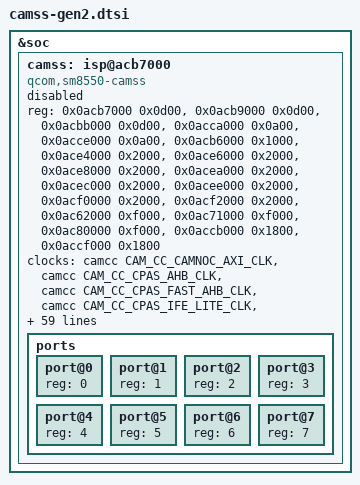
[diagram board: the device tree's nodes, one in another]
#include <dt-bindings/interrupt-controller/arm-gic.h>
#include <dt-bindings/clock/qcom,camcc-kalama.h>
#include <dt-bindings/clock/qcom,dispcc-kalama.h>
#include <dt-bindings/clock/qcom,gcc-kalama.h>
#include <dt-bindings/clock/qcom,gpucc-kalama.h>
#include <dt-bindings/clock/qcom,rpmh.h>
#include <dt-bindings/clock/qcom,tcsrcc-kalama.h>
#include <dt-bindings/clock/qcom,videocc-kalama.h>
#include <dt-bindings/regulator/qcom,rpmh-regulator-levels.h>
#include <dt-bindings/interconnect/qcom,kalama.h>
#include <dt-bindings/soc/qcom,ipcc.h>
#include <dt-bindings/soc/qcom,rpmh-rsc.h>
#include <dt-bindings/interconnect/qcom,icc.h>
#include <dt-bindings/spmi/spmi.h>
#include <dt-bindings/power/qcom-aoss-qmp.h>
#include <dt-bindings/clock/qcom,aop-qmp.h>

#include "camss-cci.dtsi"

&soc {
	#address-cells = <1>;
	#size-cells = <1>;

	camss: isp@acb7000 {
		compatible = "qcom,sm8550-camss";
		status = "disabled";

		reg = <0x0acb7000 0x0d00>,
		      <0x0acb9000 0x0d00>,
		      <0x0acbb000 0x0d00>,
		      <0x0acca000 0x0a00>,
		      <0x0acce000 0x0a00>,
		      <0x0acb6000 0x1000>,
		      <0x0ace4000 0x2000>,
		      <0x0ace6000 0x2000>,
		      <0x0ace8000 0x2000>,
		      <0x0acea000 0x2000>,
		      <0x0acec000 0x2000>,
		      <0x0acee000 0x2000>,
		      <0x0acf0000 0x2000>,
		      <0x0acf2000 0x2000>,
		      <0x0ac62000 0xf000>,
		      <0x0ac71000 0xf000>,
		      <0x0ac80000 0xf000>,
		      <0x0accb000 0x1800>,
		      <0x0accf000 0x1800>;
		reg-names = "csid0",
			    "csid1",
			    "csid2",
			    "csid_lite0",
			    "csid_lite1",
			    "csid_wrapper",
			    "csiphy0",
			    "csiphy1",
			    "csiphy2",
			    "csiphy3",
			    "csiphy4",
			    "csiphy5",
			    "csiphy6",
			    "csiphy7",
			    "vfe0",
			    "vfe1",
			    "vfe2",
			    "vfe_lite0",
			    "vfe_lite1";

		clocks = <&camcc CAM_CC_CAMNOC_AXI_CLK>,
			 <&camcc CAM_CC_CPAS_AHB_CLK>,
			 <&camcc CAM_CC_CPAS_FAST_AHB_CLK>,
			 <&camcc CAM_CC_CPAS_IFE_LITE_CLK>,
			 <&camcc CAM_CC_CPAS_IFE_0_CLK>,
			 <&camcc CAM_CC_CPAS_IFE_1_CLK>,
			 <&camcc CAM_CC_CPAS_IFE_2_CLK>,
			 <&camcc CAM_CC_CSID_CLK>,
			 <&camcc CAM_CC_CSIPHY0_CLK>,
			 <&camcc CAM_CC_CSI0PHYTIMER_CLK>,
			 <&camcc CAM_CC_CSIPHY1_CLK>,
			 <&camcc CAM_CC_CSI1PHYTIMER_CLK>,
			 <&camcc CAM_CC_CSIPHY2_CLK>,
			 <&camcc CAM_CC_CSI2PHYTIMER_CLK>,
			 <&camcc CAM_CC_CSIPHY3_CLK>,
			 <&camcc CAM_CC_CSI3PHYTIMER_CLK>,
			 <&camcc CAM_CC_CSIPHY4_CLK>,
			 <&camcc CAM_CC_CSI4PHYTIMER_CLK>,
			 <&camcc CAM_CC_CSIPHY5_CLK>,
			 <&camcc CAM_CC_CSI5PHYTIMER_CLK>,
			 <&camcc CAM_CC_CSIPHY6_CLK>,
			 <&camcc CAM_CC_CSI6PHYTIMER_CLK>,
			 <&camcc CAM_CC_CSIPHY7_CLK>,
			 <&camcc CAM_CC_CSI7PHYTIMER_CLK>,
			 <&camcc CAM_CC_CSID_CSIPHY_RX_CLK>,
			 <&gcc GCC_CAMERA_HF_AXI_CLK>,
			 <&camcc CAM_CC_IFE_0_CLK>,
			 <&camcc CAM_CC_IFE_0_FAST_AHB_CLK>,
			 <&camcc CAM_CC_IFE_1_CLK>,
			 <&camcc CAM_CC_IFE_1_FAST_AHB_CLK>,
			 <&camcc CAM_CC_IFE_2_CLK>,
			 <&camcc CAM_CC_IFE_2_FAST_AHB_CLK>,
			 <&camcc CAM_CC_IFE_LITE_CLK>,
			 <&camcc CAM_CC_IFE_LITE_AHB_CLK>,
			 <&camcc CAM_CC_IFE_LITE_CPHY_RX_CLK>,
			 <&camcc CAM_CC_IFE_LITE_CSID_CLK>;
		clock-names = "camnoc_axi",
			      "cpas_ahb",
			      "cpas_fast_ahb_clk",
			      "cpas_ife_lite",
			      "cpas_vfe0",
			      "cpas_vfe1",
			      "cpas_vfe2",
			      "csid",
			      "csiphy0",
			      "csiphy0_timer",
			      "csiphy1",
			      "csiphy1_timer",
			      "csiphy2",
			      "csiphy2_timer",
			      "csiphy3",
			      "csiphy3_timer",
			      "csiphy4",
			      "csiphy4_timer",
			      "csiphy5",
			      "csiphy5_timer",
			      "csiphy6",
			      "csiphy6_timer",
			      "csiphy7",
			      "csiphy7_timer",
			      "csiphy_rx",
			      "gcc_axi_hf",
			      "vfe0",
			      "vfe0_fast_ahb",
			      "vfe1",
			      "vfe1_fast_ahb",
			      "vfe2",
			      "vfe2_fast_ahb",
			      "vfe_lite",
			      "vfe_lite_ahb",
			      "vfe_lite_cphy_rx",
			      "vfe_lite_csid";

		interrupts = <GIC_SPI 601 IRQ_TYPE_EDGE_RISING>,
			     <GIC_SPI 603 IRQ_TYPE_EDGE_RISING>,
			     <GIC_SPI 431 IRQ_TYPE_EDGE_RISING>,
			     <GIC_SPI 605 IRQ_TYPE_EDGE_RISING>,
			     <GIC_SPI 376 IRQ_TYPE_EDGE_RISING>,
			     <GIC_SPI 477 IRQ_TYPE_EDGE_RISING>,
			     <GIC_SPI 478 IRQ_TYPE_EDGE_RISING>,
			     <GIC_SPI 479 IRQ_TYPE_EDGE_RISING>,
			     <GIC_SPI 448 IRQ_TYPE_EDGE_RISING>,
			     <GIC_SPI 122 IRQ_TYPE_EDGE_RISING>,
			     <GIC_SPI 89 IRQ_TYPE_EDGE_RISING>,
			     <GIC_SPI 278 IRQ_TYPE_EDGE_RISING>,
			     <GIC_SPI 277 IRQ_TYPE_EDGE_RISING>,
			     <GIC_SPI 602 IRQ_TYPE_EDGE_RISING>,
			     <GIC_SPI 604 IRQ_TYPE_EDGE_RISING>,
			     <GIC_SPI 688 IRQ_TYPE_EDGE_RISING>,
			     <GIC_SPI 606 IRQ_TYPE_EDGE_RISING>,
			     <GIC_SPI 377 IRQ_TYPE_EDGE_RISING>;
		interrupt-names = "csid0",
				  "csid1",
				  "csid2",
				  "csid_lite0",
				  "csid_lite1",
				  "csiphy0",
				  "csiphy1",
				  "csiphy2",
				  "csiphy3",
				  "csiphy4",
				  "csiphy5",
				  "csiphy6",
				  "csiphy7",
				  "vfe0",
				  "vfe1",
				  "vfe2",
				  "vfe_lite0",
				  "vfe_lite1";

		interconnects = <&gem_noc MASTER_APPSS_PROC
				 &config_noc SLAVE_CAMERA_CFG >,
				<&mmss_noc MASTER_CAMNOC_HF
				 &mc_virt SLAVE_EBI1 >;
		interconnect-names = "ahb",
				     "hf_0_mnoc";

		iommus = <&apps_smmu 0x800 0x20>;

		vdda-phy-supply = <&L1E>;
		vdda-pll-supply = <&L3E>;

		regulator-names = "gdscr";
		gdscr-supply = <&cam_cc_titan_top_gdsc>;

		ports {
			#address-cells = <1>;
			#size-cells = <0>;

			port@0 {
				reg = <0>;
			};

			port@1 {
				reg = <1>;
			};

			port@2 {
				reg = <2>;
			};

			port@3 {
				reg = <3>;
			};

			port@4 {
				reg = <4>;
			};

			port@5 {
				reg = <5>;
			};

			port@6 {
				reg = <6>;
			};

			port@7 {
				reg = <7>;
			};
		};
	};
};
